# M073 register map
File version: 2.0.2.4
Registers are 32-bit, read-write, reset 0x0 unless marked. A register's access mark holds for its fields unless they carry their own. Offsets are from the block's base; [hi:lo] are bit positions; {n}, {i} and the like mark numbered series.

## EN — Encoder Input (ENC)
Base 0x400F7100
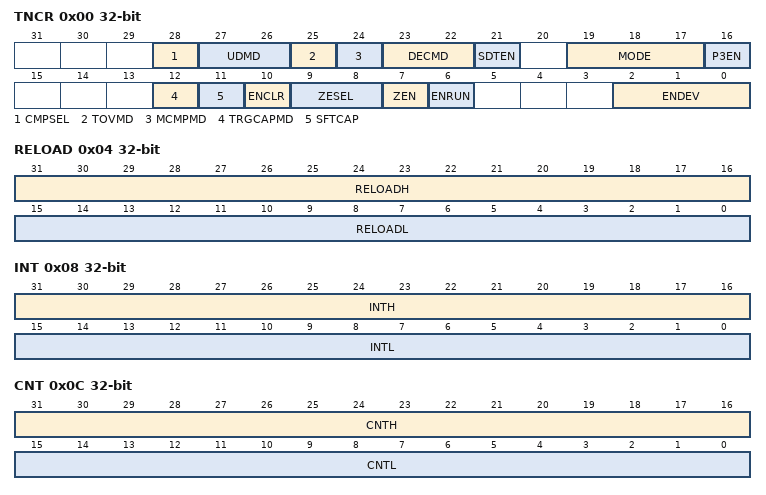
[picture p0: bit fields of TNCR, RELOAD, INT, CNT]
0x00 TNCR — Encoder Control Register
  [28] CMPSEL, [27:26] UDMD, [25] TOVMD, [24] MCMPMD, [23:22] DECMD, [21] SDTEN, [19:17] MODE, [16] P3EN, [12] TRGCAPMD, [11] SFTCAP wo, [10] ENCLR wo, [9:8] ZESEL, [7] ZEN, [6] ENRUN, [2:0] ENDEV
0x04 RELOAD — Reload Compare Register
  [31:16] RELOADH, [15:0] RELOADL
0x08 INT — INT Compare Register
  [31:16] INTH, [15:0] INTL
0x0C CNT — Counter_Capture Register
  [31:16] CNTH, [15:0] CNTL
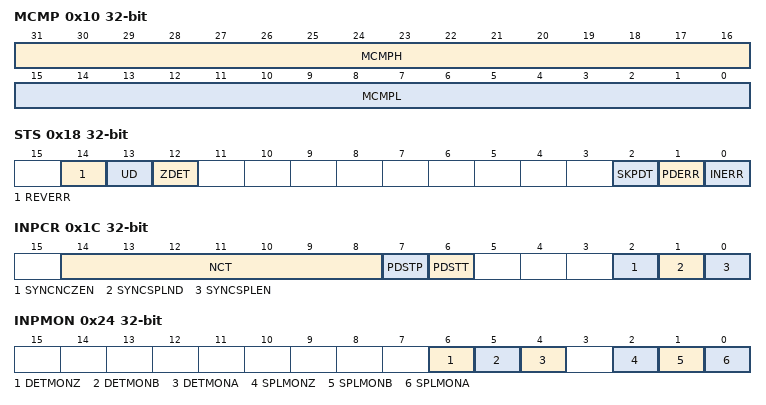
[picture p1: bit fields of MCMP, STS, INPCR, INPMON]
0x10 MCMP — MCMP Compare Register
  [31:16] MCMPH, [15:0] MCMPL
0x14 RATE — Phase Count Rate Register
  [15:0] RATE
0x18 STS ro — Status Register
  [14] REVERR, [13] UD, [12] ZDET, [2] SKPDT, [1] PDERR, [0] INERR
0x1C INPCR — Input Process Cntrol Register
  [14:8] NCT, [7] PDSTP wo, [6] PDSTT wo, [2] SYNCNCZEN, [1] SYNCSPLND, [0] SYNCSPLEN
0x20 SMPDLY — Sample Delay Register
  [7:0] SMPDLY
0x24 INPMON ro — Input Moniter Register
  [6] DETMONZ, [5] DETMONB, [4] DETMONA, [2] SPLMONZ, [1] SPLMONB, [0] SPLMONA
0x28 CLKCR — Sample Clock Control Register
  [1:0] SPLCLKS
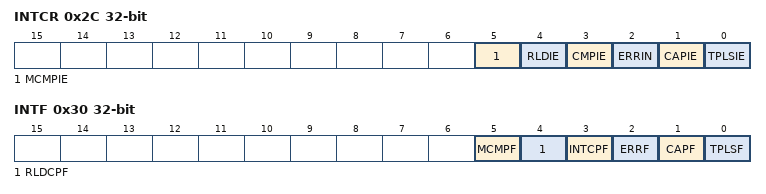
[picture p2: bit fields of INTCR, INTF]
0x2C INTCR — Interrupt Reqyest Control Register
  [5] MCMPIE, [4] RLDIE, [3] CMPIE, [2] ERRIN, [1] CAPIE, [0] TPLSIE
0x30 INTF ro — Interrupt Event Flag Register
  [5] MCMPF, [4] RLDCPF, [3] INTCPF, [2] ERRF, [1] CAPF, [0] TPLSF

## AD — Analog-to-Digital Converter (AD)
Base 0x400FD100
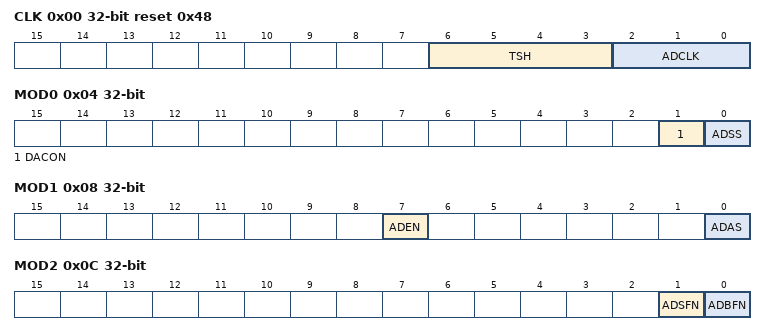
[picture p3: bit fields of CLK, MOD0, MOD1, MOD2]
0x00 CLK reset 0x48 — AD Conversion Clock Setting Register
  [6:3] TSH, [2:0] ADCLK
0x04 MOD0 — AD Mode Setting Register 0
  [1] DACON, [0] ADSS wo
0x08 MOD1 — AD Mode Setting Register 1
  [7] ADEN, [0] ADAS
0x0C MOD2 ro — AD Mode Setting Register 2
  [1] ADSFN, [0] ADBFN
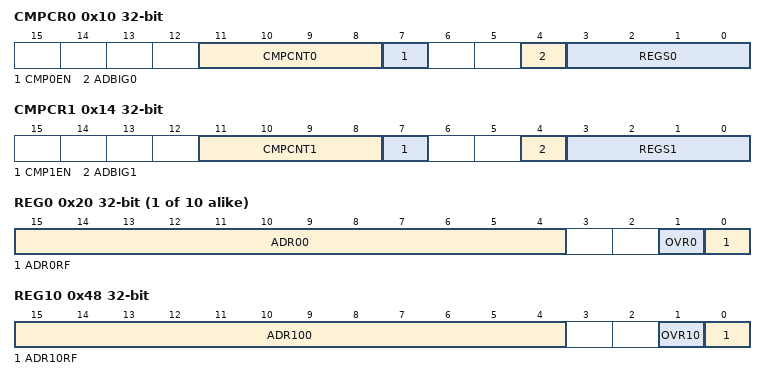
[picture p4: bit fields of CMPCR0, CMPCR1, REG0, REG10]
0x10 CMPCR0 — AD Monitoring Setting Register 0
  [11:8] CMPCNT0, [7] CMP0EN, [4] ADBIG0, [3:0] REGS0
0x14 CMPCR1 — AD Monitoring Setting Register 1
  [11:8] CMPCNT1, [7] CMP1EN, [4] ADBIG1, [3:0] REGS1
0x18 CMP0 — AD Conversion Result Compare Register 0
  [15:4] AD0CMP0
0x1C CMP1 — AD Conversion Result Compare Register 1
  [15:4] AD0CMP1
{0x20+4i} REG{i} ro (i=0..9) — AD Conversion Result Register {i}
  [15:4] ADR{10i:02}, [1] OVR{i}, [0] ADR{i}RF
0x48 REG10 ro — AD Conversion Result Register 10
  [15:4] ADR100, [1] OVR10, [0] ADR10RF
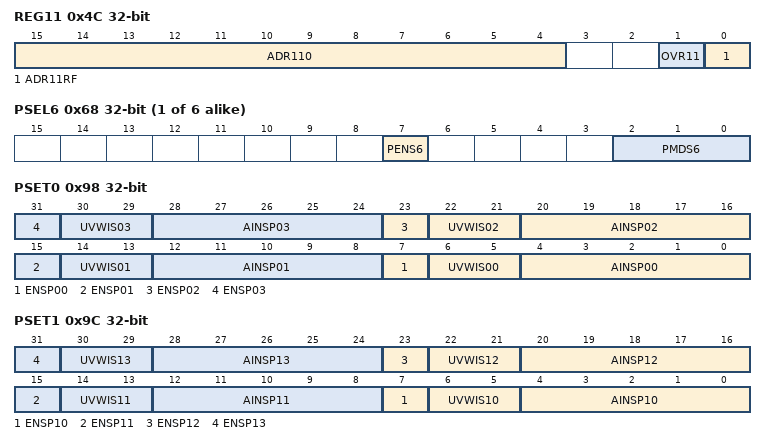
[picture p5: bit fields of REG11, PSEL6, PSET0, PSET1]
0x4C REG11 ro — AD Conversion Result Register 11
  [15:4] ADR110, [1] OVR11, [0] ADR11RF
{0x50+4i} PSEL{i} (i=6..11) — PMD Trigger Program Number Select Register {i}
  [7] PENS{i}, [2:0] PMDS{i}
{0x80+4i} PINTS{i} (i=0..5) — PMD Trigger Interrupt Select Register {i}
  [1:0] INTSEL{i}
0x98 PSET0 — PMD Trigger Program Register 0
  [8n+7] ENSP{n:02} (n=0..3), [8n+6:8n+5] UVWIS{n:02} (n=0..3), [8n+4:8n] AINSP{n:02} (n=0..3)
0x9C PSET1 — PMD Trigger Program Register 1
  [8n-73] ENSP{n} (n=10..13), [8n-74:8n-75] UVWIS{n} (n=10..13), [8n-76:8n-80] AINSP{n} (n=10..13)
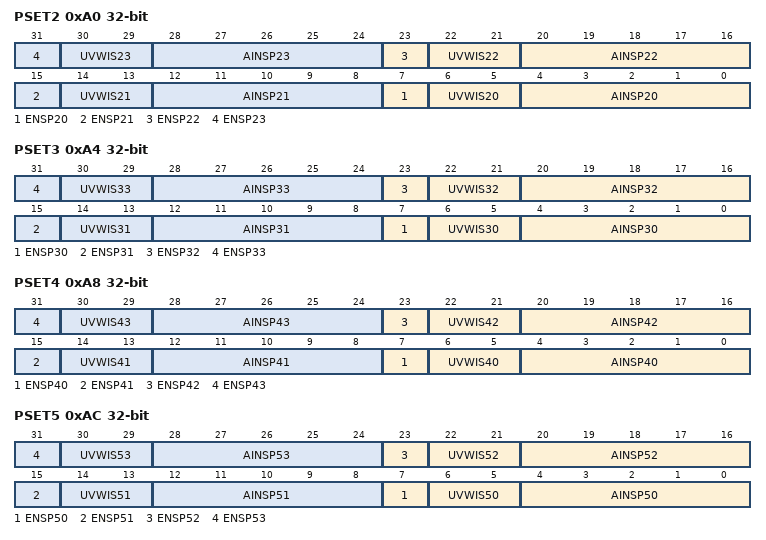
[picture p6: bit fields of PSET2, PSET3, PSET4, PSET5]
0xA0 PSET2 — PMD Trigger Program Register 2
  [8n-153] ENSP{n} (n=20..23), [8n-154:8n-155] UVWIS{n} (n=20..23), [8n-156:8n-160] AINSP{n} (n=20..23)
0xA4 PSET3 — PMD Trigger Program Register 3
  [8n-233] ENSP{n} (n=30..33), [8n-234:8n-235] UVWIS{n} (n=30..33), [8n-236:8n-240] AINSP{n} (n=30..33)
0xA8 PSET4 — PMD Trigger Program Register 4
  [8n-313] ENSP{n} (n=40..43), [8n-314:8n-315] UVWIS{n} (n=40..43), [8n-316:8n-320] AINSP{n} (n=40..43)
0xAC PSET5 — PMD Trigger Program Register 5
  [8n-393] ENSP{n} (n=50..53), [8n-394:8n-395] UVWIS{n} (n=50..53), [8n-396:8n-400] AINSP{n} (n=50..53)
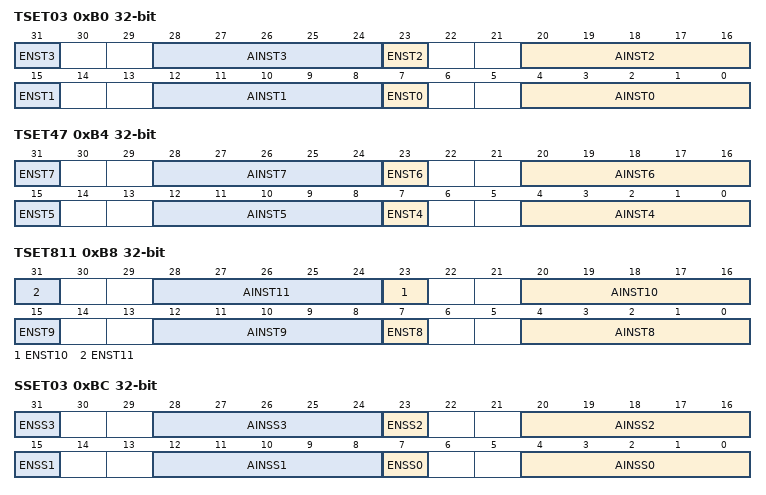
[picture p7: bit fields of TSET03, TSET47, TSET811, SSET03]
0xB0 TSET03 — Timer Trigger Program Register 03
  [8n+7] ENST{n} (n=0..3), [8n+4:8n] AINST{n} (n=0..3)
0xB4 TSET47 — Timer Trigger Program Register 47
  [8n-25] ENST{n} (n=4..7), [8n-28:8n-32] AINST{n} (n=4..7)
0xB8 TSET811 — Timer Trigger Program Register 811
  [8n-57] ENST{n} (n=8..11), [8n-60:8n-64] AINST{n} (n=8..11)
0xBC SSET03 — Software Trigger Program Register 03
  [8n+7] ENSS{n} (n=0..3), [8n+4:8n] AINSS{n} (n=0..3)
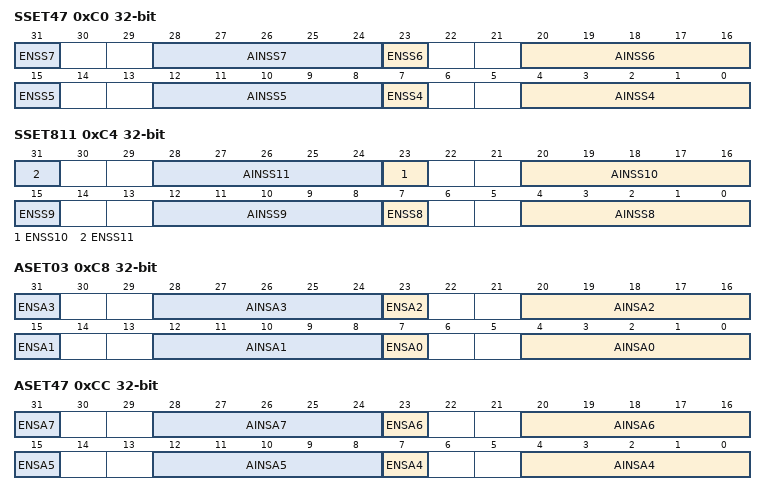
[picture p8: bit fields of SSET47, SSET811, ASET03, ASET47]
0xC0 SSET47 — Software Trigger Program Register 47
  [8n-25] ENSS{n} (n=4..7), [8n-28:8n-32] AINSS{n} (n=4..7)
0xC4 SSET811 — Software Trigger Program Register 811
  [8n-57] ENSS{n} (n=8..11), [8n-60:8n-64] AINSS{n} (n=8..11)
0xC8 ASET03 — Constant Conversion Program Register 03
  [8n+7] ENSA{n} (n=0..3), [8n+4:8n] AINSA{n} (n=0..3)
0xCC ASET47 — Constant Conversion Program Register 47
  [8n-25] ENSA{n} (n=4..7), [8n-28:8n-32] AINSA{n} (n=4..7)
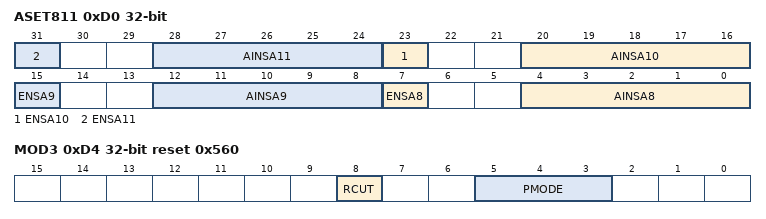
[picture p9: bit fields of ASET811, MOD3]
0xD0 ASET811 — Constant Conversion Program Register 811
  [8n-57] ENSA{n} (n=8..11), [8n-60:8n-64] AINSA{n} (n=8..11)
0xD4 MOD3 reset 0x560 — Mode setting Register3
  [8] RCUT, [5:3] PMODE

## FC — Flash Control (FC)
Base 0x41FFF000
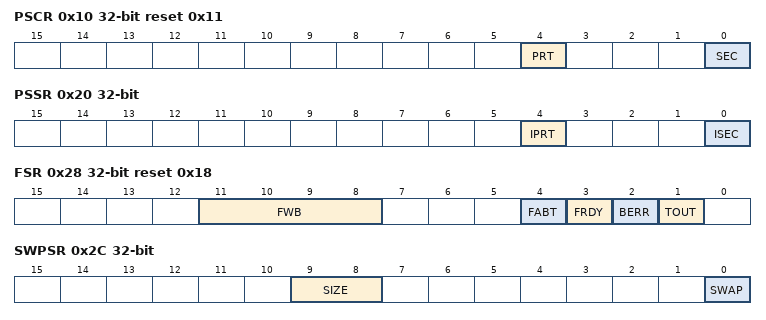
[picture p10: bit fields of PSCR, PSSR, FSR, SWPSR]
0x10 PSCR reset 0x11 — Protect Security Control Register
  [4] PRT, [0] SEC
0x20 PSSR ro — Protect Security Status Register
  [4] IPRT, [0] ISEC
0x28 FSR ro reset 0x18 — FC Status Register
  [11:8] FWB, [4] FABT, [3] FRDY, [2] BERR, [1] TOUT
0x2C SWPSR ro — Memory Swap Status Register
  [9:8] SIZE, [0] SWAP
0x30 PRGSR ro reset 0x1 — Program Status Register
  [0] RDY_BSY
0x34 MCR — Mode Control Register
  [5:3] FMOD
0x38 KYCR — Flash Key Code Register
  [31:0] KEYCODE
0x3C WEACR — Flash Abort Control Register
  [2:0] WEABT
0x54 WAITCR reset 0x7 — Flash Wait Control Register
  [2:0] WAIT
